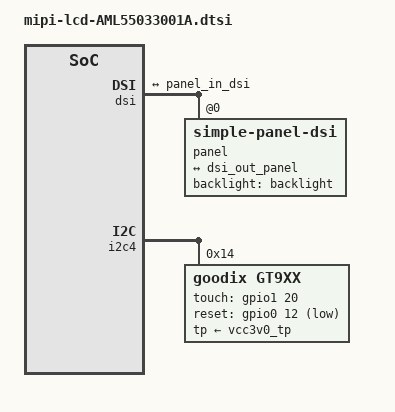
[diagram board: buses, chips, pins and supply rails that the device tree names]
/*
 * Copyright (c) 2022 Biandenhuo Co., Ltd
 */

&dsi {
	//rockchip,lane-rate = <420>;     // 62MHz(Pixel Clock) * 3(Pixel Clock Divider) * 2 (Double Data Rate) = 372Mbps
	status = "okay";

	panel@0 {
		compatible = "simple-panel-dsi";
		reg = <0>;
		backlight = <&backlight>;

		/*reset-gpios = <&gpio4 29 GPIO_ACTIVE_LOW>;*/      /*GPIO4_D5*/
		/*enable-gpios = <&gpio4 22 GPIO_ACTIVE_HIGH>;*/     /*GPIO4_C6*/

		prepare-delay-ms = <20>;
		reset-delay-ms = <20>;
		init-delay-ms = <20>;
		enable-delay-ms = <20>;
		disable-delay-ms = <20>;
		unprepare-delay-ms = <20>;
		
		dsi,flags = <(MIPI_DSI_MODE_VIDEO | MIPI_DSI_MODE_VIDEO_BURST)>;
		dsi,format = <MIPI_DSI_FMT_RGB888>;
		dsi,lanes = <4>;

		/*AML55033001A HI8558A_DS_720P*/
		panel-init-sequence = [
				15 00 02 E0 00
				15 00 02 E1 93
				15 00 02 E2 65
				15 00 02 E3 F8
				15 00 02 80 03
				15 00 02 E0 01
				15 00 02 00 00
				15 00 02 01 86
				15 00 02 03 00
				15 00 02 04 88
				15 00 02 17 00
				15 00 02 18 D7
				15 00 02 19 00
				15 00 02 1A 00
				15 00 02 1B D7
				15 00 02 1C 00
				15 00 02 22 6C
				15 00 02 23 02
				15 00 02 24 FA
				15 00 02 37 09
				15 00 02 40 04
				15 00 02 41 A0
				15 00 02 42 A0
				15 00 02 43 0D
				15 00 02 44 0C
				15 00 02 45 76
				15 00 02 4B 04
				15 00 02 55 02
				15 00 02 57 69
				15 00 02 5A 29
				15 00 02 5B 11
				15 00 02 5D 78
				15 00 02 5E 62
				15 00 02 5F 54
				15 00 02 60 49
				15 00 02 61 47
				15 00 02 62 39
				15 00 02 63 40
				15 00 02 64 2C
				15 00 02 65 46
				15 00 02 66 46
				15 00 02 67 46
				15 00 02 68 63
				15 00 02 69 50
				15 00 02 6A 56
				15 00 02 6B 47
				15 00 02 6C 40
				15 00 02 6D 32
				15 00 02 6E 1F
				15 00 02 6F 0F
				15 00 02 70 78
				15 00 02 71 62
				15 00 02 72 54
				15 00 02 73 49
				15 00 02 74 47
				15 00 02 75 39
				15 00 02 76 40
				15 00 02 77 2C
				15 00 02 78 46
				15 00 02 79 46
				15 00 02 7A 46
				15 00 02 7B 63
				15 00 02 7C 50
				15 00 02 7D 56
				15 00 02 7E 47
				15 00 02 7F 40
				15 00 02 80 32
				15 00 02 81 1F
				15 00 02 82 0F
				15 00 02 84 02
				15 00 02 85 A9
				15 00 02 E0 02
				15 00 02 00 5E
				15 00 02 01 5F
				15 00 02 02 57
				15 00 02 03 58
				15 00 02 04 44
				15 00 02 05 46
				15 00 02 06 48
				15 00 02 07 4A
				15 00 02 08 40
				15 00 02 09 5F
				15 00 02 0A 5F
				15 00 02 0B 5F
				15 00 02 0C 5F
				15 00 02 0D 5F
				15 00 02 0E 5F
				15 00 02 0F 50
				15 00 02 10 5F
				15 00 02 11 5F
				15 00 02 12 5F
				15 00 02 13 5F
				15 00 02 14 5F
				15 00 02 15 5F
				15 00 02 16 5E
				15 00 02 17 5F
				15 00 02 18 57
				15 00 02 19 58
				15 00 02 1A 45
				15 00 02 1B 47
				15 00 02 1C 49
				15 00 02 1D 4B
				15 00 02 1E 41
				15 00 02 1F 5F
				15 00 02 20 5F
				15 00 02 21 5F
				15 00 02 22 5F
				15 00 02 23 5F
				15 00 02 24 5F
				15 00 02 25 51
				15 00 02 26 5F
				15 00 02 27 5F
				15 00 02 28 5F
				15 00 02 29 5F
				15 00 02 2A 5F
				15 00 02 2B 5F
				15 00 02 2C 1F
				15 00 02 2D 1E
				15 00 02 2E 17
				15 00 02 2F 18
				15 00 02 30 0B
				15 00 02 31 09
				15 00 02 32 07
				15 00 02 33 05
				15 00 02 34 11
				15 00 02 35 1F
				15 00 02 36 1F
				15 00 02 37 1F
				15 00 02 38 1F
				15 00 02 39 1F
				15 00 02 3A 1F
				15 00 02 3B 01
				15 00 02 3C 1F
				15 00 02 3D 1F
				15 00 02 3E 1F
				15 00 02 3F 1F
				15 00 02 40 1F
				15 00 02 41 1F
				15 00 02 42 1F
				15 00 02 43 1E
				15 00 02 44 17
				15 00 02 45 18
				15 00 02 46 0A
				15 00 02 47 08
				15 00 02 48 06
				15 00 02 49 04
				15 00 02 4A 10
				15 00 02 4B 1F
				15 00 02 4C 1F
				15 00 02 4D 1F
				15 00 02 4E 1F
				15 00 02 4F 1F
				15 00 02 50 1F
				15 00 02 51 00
				15 00 02 52 1F
				15 00 02 53 1F
				15 00 02 54 1F
				15 00 02 55 1F
				15 00 02 56 1F
				15 00 02 57 1F
				15 00 02 5B 10
				15 00 02 5C 08
				15 00 02 5D 30
				15 00 02 5E 01
				15 00 02 5F 02
				15 00 02 60 30
				15 00 02 61 03
				15 00 02 62 04
				15 00 02 63 32
				15 00 02 64 3F
				15 00 02 65 75
				15 00 02 66 0C
				15 00 02 67 73
				15 00 02 68 0A
				15 00 02 69 32
				15 00 02 6A 3F
				15 00 02 6B 08
				15 00 02 6C 32
				15 00 02 6D 3F
				15 00 02 6F 04
				15 00 02 70 04
				15 00 02 71 88
				15 00 02 77 BC
				15 00 02 78 00
				15 00 02 79 0D
				15 00 02 7A 22
				15 00 02 E0 04
				15 00 02 31 10
				15 00 02 35 0E
				15 00 02 36 19
				15 00 02 99 03
				15 00 02 A8 0F
				15 00 02 A4 01
				15 00 02 A5 9C
				15 00 02 50 6E
				15 00 02 51 CC
				15 00 02 52 02
				15 00 02 53 0F
				15 00 02 E0 07
				15 00 02 90 00
				15 00 02 E0 00
				15 00 02 E6 02
				15 00 02 E7 1F
				15 78 02 11 00
				15 05 02 29 00
		];

		display-timings {
			native-mode = <&timing0>;
			timing0: timing0 {
				clock-frequency = <61620000>;
				hactive = <720>;
				vactive = <1280>;

				hsync-len = <20>;
				hback-porch = <20>;
				hfront-porch = <30>;

				vsync-len = <2>;
				vback-porch = <5>;
				vfront-porch = <13>;

				hsync-active = <0>;
				vsync-active = <0>;
				de-active = <0>;
				pixelclk-active = <0>;
			};
		};		

		ports {
			#address-cells = <1>;
			#size-cells = <0>;
			
			port@0 {
			        reg = <0>;
			        panel_in_dsi: endpoint {
			                remote-endpoint = <&dsi_out_panel>;
			        };
			};
		};

	};

	ports {
		#address-cells = <1>;
		#size-cells = <0>;
		port@1 {
			reg = <1>;
			dsi_out_panel: endpoint {
				remote-endpoint = <&panel_in_dsi>;
			};
		};
	};

};

&i2c4 {
	gt9xx: gt9xx@14 {
		compatible = "goodix,gt9xx";
		reg = <0x14>;
		//touch-gpio = <&gpio4 28 IRQ_TYPE_LEVEL_LOW>; /*GPIO4_D4 TE on LCD*/
		touch-gpio = <&gpio1 20 IRQ_TYPE_LEVEL_LOW>; /*GPIO1_C4*/
		reset-gpio = <&gpio0 12 GPIO_ACTIVE_LOW>; /*GPIO0_B4*/
                pinctrl-names = "default";
                pinctrl-0 = <&touch_io>;
		max-x = <720>;
		max-y = <1280>;
		tp-size = <911>;
		tp-supply = <&vcc3v0_tp>;
	};
};
